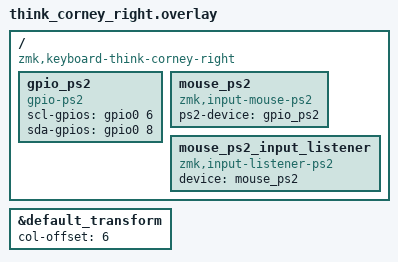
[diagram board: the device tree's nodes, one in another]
#include "think_corney.dtsi"
#include <dt-bindings/gpio/gpio.h>

/ {
  compatible = "zmk,keyboard-think-corney-right";
};

&default_transform {
  col-offset = <6>;
};

/*
 * TrackPoint / PS/2 mouse module (infused-kim/kb_zmk_ps2_mouse_trackpoint_driver)
 *
 * IMPORTANT: pins below are nice!nano "D" pins:
 *   D1 = P0.06  (clock)
 *   D0 = P0.08  (data)
 *
 * We intentionally use the GPIO (bit-banged) PS/2 transport here because it is
 * the most portable across ZMK/Zephyr versions and avoids hard-coding UART/pinctrl
 * node labels that can differ between versions.
 */

 / {
  gpio_ps2: gpio_ps2 {
    status = "okay";
    compatible = "gpio-ps2";
    /* Clock (SCL) = D1 = P0.06 */
    scl-gpios = <&gpio0 6 GPIO_ACTIVE_HIGH>;
    /* Data  (SDA) = D0 = P0.08 */
    sda-gpios = <&gpio0 8 GPIO_ACTIVE_HIGH>;
  };

  mouse_ps2: mouse_ps2 {
    status = "okay";
    compatible = "zmk,input-mouse-ps2";
    ps2-device = <&gpio_ps2>;
  };

  mouse_ps2_input_listener: mouse_ps2_input_listener {
    compatible = "zmk,input-listener-ps2";
    status = "okay";
    device = <&mouse_ps2>;
  };
};
